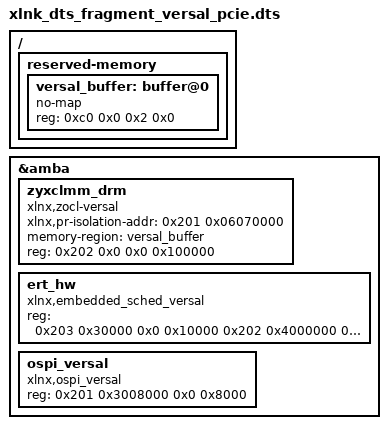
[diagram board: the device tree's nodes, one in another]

/{
        reserved-memory {
                #address-cells = <2>;
                #size-cells = <2>;
                ranges;

                versal_buffer: buffer@0 {
                        no-map;
                        reg = <0xc0 0x0 0x2 0x0>;
                };
        };
};

&amba {
        zyxclmm_drm {
                compatible = "xlnx,zocl-versal";
                status = "okay";
                xlnx,pr-isolation-addr = <0x201 0x06070000>;
                memory-region = <&versal_buffer>;
                reg = <0x202 0x0 0x0 0x100000>;
        };

        ert_hw {
                compatible = "xlnx,embedded_sched_versal";
                status = "okay";
                reg = <0x203 0x30000 0x0 0x10000 0x202 0x4000000 0x0 0x10000>;
        };

	ospi_versal {
		compatible = "xlnx,ospi_versal";
		status = "okay";
		reg = <0x201 0x3008000 0x0 0x8000>;
	};
};
